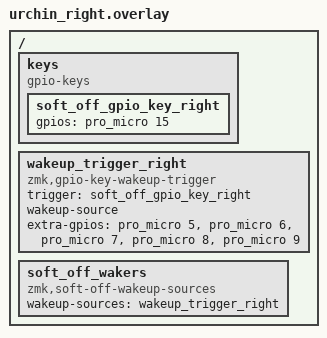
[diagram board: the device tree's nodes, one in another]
/ {
    keys {
        compatible = "gpio-keys";
        soft_off_gpio_key_right: soft_off_gpio_key_right {
            gpios = <&pro_micro 15 (GPIO_ACTIVE_HIGH | GPIO_PULL_DOWN)>;
        };
    };

    wakeup_trigger_right: wakeup_trigger_right {
        compatible = "zmk,gpio-key-wakeup-trigger";
        trigger = <&soft_off_gpio_key_right>;
        wakeup-source;
        
        extra-gpios = 
            <&pro_micro 5 GPIO_ACTIVE_HIGH>,
            <&pro_micro 6 GPIO_ACTIVE_HIGH>,
            <&pro_micro 7 GPIO_ACTIVE_HIGH>,
            <&pro_micro 8 GPIO_ACTIVE_HIGH>,
            <&pro_micro 9 GPIO_ACTIVE_HIGH>;
    };

    soft_off_wakers {
        compatible = "zmk,soft-off-wakeup-sources";
        wakeup-sources = <&wakeup_trigger_right>;
    };
};
